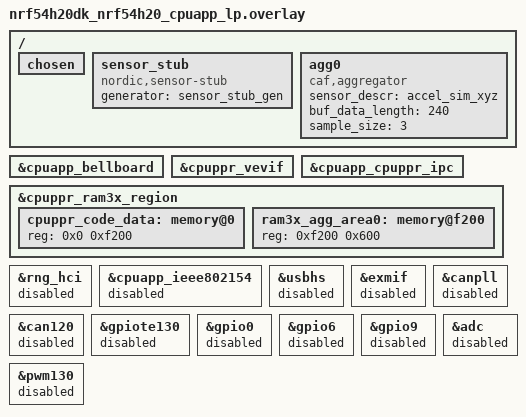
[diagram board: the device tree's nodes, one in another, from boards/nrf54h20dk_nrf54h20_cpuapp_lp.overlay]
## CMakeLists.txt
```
#
# Copyright (c) 2022 Nordic Semiconductor
#
# SPDX-License-Identifier: LicenseRef-Nordic-5-Clause
#
cmake_minimum_required(VERSION 3.20.0)

find_package(Zephyr REQUIRED HINTS $ENV{ZEPHYR_BASE})
project("Sensor manager sample")

target_sources(app PRIVATE src/main.c)

# Add include directory for board specific CAF def files
zephyr_include_directories(
  configuration/
  configuration/${NORMALIZED_BOARD_TARGET}
)

add_subdirectory(src/modules)
```

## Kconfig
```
#
# Copyright (c) 2022 Nordic Semiconductor ASA
#
# SPDX-License-Identifier: LicenseRef-Nordic-5-Clause
#

menu "Sensor manager sample"
rsource "src/modules/Kconfig"
endmenu

menu "Zephyr Kernel"
source "Kconfig.zephyr"
endmenu
```

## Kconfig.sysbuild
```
#
# Copyright (c) 2024 Nordic Semiconductor ASA
#
# SPDX-License-Identifier: LicenseRef-Nordic-5-Clause
#

config INCLUDE_REMOTE_IMAGE
	bool "Include CAF Sensor Manager remote image"
	default y

config REMOTE_BOARD
	string
	default "nrf5340dk/nrf5340/cpunet" if BOARD_NRF5340DK_NRF5340_CPUAPP
	default "nrf5340dk/nrf5340/cpunet" if BOARD_NRF5340DK_NRF5340_CPUAPP_NS
	default "nrf54h20dk/nrf54h20/cpuppr" if BOARD_NRF54H20DK_NRF54H20_CPUAPP

source "share/sysbuild/Kconfig"
```

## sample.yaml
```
sample:
  description: Sample showing CAF sensor manager usage
  name: CAF sensor manager sample

tests:
  sample.caf_sensor_manager.correctness_test:
    sysbuild: true
    build_only: false
    harness: console
    platform_allow:
      - nrf52840dk/nrf52840
      - nrf5340dk/nrf5340/cpuapp
      - qemu_cortex_m3
    integration_platforms:
      - nrf52840dk/nrf52840
      - nrf5340dk/nrf5340/cpuapp
      - qemu_cortex_m3
    harness_config:
      type: multi_line
      ordered: true
      regex:
        - "main: Event manager initialized"
        - "main state:READY"
        - "Send sensor buffer desc address:"
        - "sensor_data_aggregator_release_buffer_event"
    tags:
      - sysbuild
      - ci_samples_caf_sensor_manager
  sample.caf_sensor_manager.nrf52840dk.power_consumption_test:
    sysbuild: true
    build_only: true
    platform_allow: nrf52840dk/nrf52840
    integration_platforms:
      - nrf52840dk/nrf52840
    extra_args:
      - CONFIG_SERIAL=n
      - CONFIG_CONSOLE=n
      - CONFIG_UART_CONSOLE=n
      - CONFIG_LOG=n
    tags:
      - sysbuild
      - ci_samples_caf_sensor_manager
  sample.caf_sensor_manager.multi_core.power_consumption_test:
    sysbuild: true
    build_only: true
    platform_allow: nrf5340dk/nrf5340/cpuapp
    integration_platforms:
      - nrf5340dk/nrf5340/cpuapp
    extra_args:
      - CONFIG_SERIAL=n
      - CONFIG_CONSOLE=n
      - CONFIG_UART_CONSOLE=n
      - CONFIG_LOG=n
      - remote_CONFIG_SERIAL=n
      - remote_CONFIG_CONSOLE=n
      - remote_CONFIG_UART_CONSOLE=n
      - remote_CONFIG_LOG=n
    tags:
      - sysbuild
      - ci_samples_caf_sensor_manager
  sample.caf_sensor_manager.nrf5340dk_singlecore.power_consumption_test:
    sysbuild: true
    build_only: true
    platform_allow: nrf5340dk/nrf5340/cpuapp
    integration_platforms:
      - nrf5340dk/nrf5340/cpuapp
    extra_args:
      - FILE_SUFFIX=singlecore
      - CONFIG_CONSOLE=n
      - CONFIG_UART_CONSOLE=n
      - CONFIG_LOG=n
    tags:
      - sysbuild
      - ci_samples_caf_sensor_manager
  sample.caf_sensor_manager.nrf5340dk_singlecore.correctness_test:
    sysbuild: true
    build_only: false
    platform_allow: nrf5340dk/nrf5340/cpuapp
    integration_platforms:
      - nrf5340dk/nrf5340/cpuapp
    extra_args: FILE_SUFFIX=singlecore
    harness: console
    harness_config:
      type: multi_line
      ordered: true
      regex:
        - "main: Event manager initialized"
        - "main state:READY"
        - "Send sensor buffer desc address:"
        - "sensor_data_aggregator_release_buffer_event"
    tags:
      - sysbuild
      - ci_samples_caf_sensor_manager
  sample.caf_sensor_manager.nrf54h20.multicore:
    build_only: true
    sysbuild: true
    platform_allow:
      - nrf54h20dk/nrf54h20/cpuapp
    integration_platforms:
      - nrf54h20dk/nrf54h20/cpuapp
    extra_args: caf_sensor_manager_SNIPPET=nordic-ppr
    tags:

      - sysbuild
      - ci_samples_caf_sensor_manager
  sample.caf_sensor_manager.nrf54h20.singlecore:
    build_only: true
    sysbuild: true
    platform_allow:
      - nrf54h20dk/nrf54h20/cpuapp
    integration_platforms:
      - nrf54h20dk/nrf54h20/cpuapp
    extra_args: FILE_SUFFIX=singlecore
    tags:
      - sysbuild
      - ci_samples_caf_sensor_manager
  sample.caf_sensor_manager.nrf54h20.multicore.power_consumption_test:
    build_only: true
    sysbuild: true
    platform_allow:
      - nrf54h20dk/nrf54h20/cpuapp
    integration_platforms:
      - nrf54h20dk/nrf54h20/cpuapp
    extra_args:
      - caf_sensor_manager_SNIPPET=nordic-ppr
      - SB_CONFIG_NETCORE_EMPTY=y
      - CONFIG_PM=y
    tags:
      - sysbuild
      - ci_samples_caf_sensor_manager
  sample.caf_sensor_manager.nrf54h20.singlecore.power_consumption_test:
    build_only: true
    sysbuild: true
    platform_allow:
      - nrf54h20dk/nrf54h20/cpuapp
    integration_platforms:
      - nrf54h20dk/nrf54h20/cpuapp
    extra_args:
      - FILE_SUFFIX=singlecore
      - SB_CONFIG_NETCORE_EMPTY=y
      - CONFIG_PM=y
    tags:
      - sysbuild
      - ci_samples_caf_sensor_manager
```

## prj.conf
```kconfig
#
# Copyright (c) 2022 Nordic Semiconductor ASA
#
# SPDX-License-Identifier: LicenseRef-Nordic-5-Clause
#
################################################################################
# Application configuration

CONFIG_APP_WORKLOAD_SIM=y

CONFIG_CAF=y

CONFIG_CAF_INIT_LOG_SENSOR_EVENTS=n

CONFIG_CAF_SENSOR_DATA_AGGREGATOR_EVENTS=y

CONFIG_APP_EVENT_MANAGER=y
CONFIG_REBOOT=y
CONFIG_HEAP_MEM_POOL_SIZE=4096

################################################################################
# Debug configuration

CONFIG_ASSERT=y
CONFIG_RESET_ON_FATAL_ERROR=n

# Disable GPIO
CONFIG_GPIO=n

CONFIG_LOG=y
CONFIG_LOG_MODE_DEFERRED=y
```

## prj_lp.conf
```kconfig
#
# Copyright (c) 2025 Nordic Semiconductor ASA
#
# SPDX-License-Identifier: LicenseRef-Nordic-5-Clause
#
################################################################################
# Application configuration

CONFIG_APP_WORKLOAD_SIM=y

CONFIG_CAF=y

CONFIG_CAF_INIT_LOG_SENSOR_EVENTS=n

CONFIG_CAF_SENSOR_DATA_AGGREGATOR_EVENTS=y

CONFIG_APP_EVENT_MANAGER=y
CONFIG_REBOOT=y
CONFIG_HEAP_MEM_POOL_SIZE=4096

################################################################################
# Debug configuration

CONFIG_ASSERT=y
CONFIG_RESET_ON_FATAL_ERROR=n

# Disable GPIO
CONFIG_GPIO=n

CONFIG_LOG=y
CONFIG_LOG_MODE_DEFERRED=y

CONFIG_PM=y
CONFIG_PM_S2RAM=y
CONFIG_PM_S2RAM_CUSTOM_MARKING=y
```

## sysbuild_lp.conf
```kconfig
#
# Copyright (c) 2025 Nordic Semiconductor ASA
#
# SPDX-License-Identifier: LicenseRef-Nordic-5-Clause
#
################################################################################

SB_CONFIG_NETCORE_EMPTY=y
```

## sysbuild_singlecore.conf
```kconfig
#
# Copyright (c) 2024 Nordic Semiconductor ASA
#
# SPDX-License-Identifier: LicenseRef-Nordic-5-Clause
#
################################################################################

SB_CONFIG_INCLUDE_REMOTE_IMAGE=n
```

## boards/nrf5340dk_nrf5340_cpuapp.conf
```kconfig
#
# Copyright (c) 2022 Nordic Semiconductor ASA
#
# SPDX-License-Identifier: LicenseRef-Nordic-5-Clause
#
################################################################################

CONFIG_EVENT_MANAGER_PROXY=y
CONFIG_IPC_SERVICE=y
CONFIG_MBOX=y

CONFIG_OPENAMP=y
CONFIG_OPENAMP_SLAVE=n

CONFIG_CAF_SENSOR_DATA_AGGREGATOR_EVENTS=y

CONFIG_SOC_NRF53_CPUNET_ENABLE=y
```

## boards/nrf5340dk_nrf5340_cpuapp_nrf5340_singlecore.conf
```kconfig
#
# Copyright (c) 2022 Nordic Semiconductor ASA
#
# SPDX-License-Identifier: LicenseRef-Nordic-5-Clause
#
################################################################################

CONFIG_APP_INCLUDE_REMOTE_IMAGE=n
CONFIG_APP_REMOTE_BOARD=""

CONFIG_EVENT_MANAGER_PROXY=n
CONFIG_IPC_SERVICE=n
CONFIG_MBOX=n
CONFIG_NRF53_SYNC_RTC=n
CONFIG_OPENAMP=n

CONFIG_CAF_SENSOR_MANAGER=y

CONFIG_SENSOR=y
CONFIG_SENSOR_SIM=y
```

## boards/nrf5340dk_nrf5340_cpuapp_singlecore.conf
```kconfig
#
# Copyright (c) 2022 Nordic Semiconductor ASA
#
# SPDX-License-Identifier: LicenseRef-Nordic-5-Clause
#
################################################################################

CONFIG_EVENT_MANAGER_PROXY=n
CONFIG_IPC_SERVICE=n
CONFIG_MBOX=n
CONFIG_NRF53_SYNC_RTC=n
CONFIG_OPENAMP=n

CONFIG_CAF_SENSOR_MANAGER=y
CONFIG_CAF_SENSOR_MANAGER_THREAD_STACK_SIZE=512
CONFIG_CAF_SENSOR_DATA_AGGREGATOR=y

CONFIG_SENSOR=y
CONFIG_SENSOR_STUB=y
```

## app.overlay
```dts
/*
 * Copyright (c) 2022 Nordic Semiconductor ASA
 *
 * SPDX-License-Identifier: LicenseRef-Nordic-5-Clause
 */

/ {
	agg0: agg0 {
		compatible = "caf,aggregator";
		sensor_descr = "accel_sim_xyz";
		buf_data_length = <240>;
		sample_size = <3>;
		status = "okay";
	};
};
```

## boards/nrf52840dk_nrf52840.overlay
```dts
/*
 * Copyright (c) 2022 Nordic Semiconductor ASA
 *
 * SPDX-License-Identifier: LicenseRef-Nordic-5-Clause
 */

/ {
	sensor_stub: sensor_stub {
		compatible = "nordic,sensor-stub";
		generator = "sensor_stub_gen";
		status = "okay";
	};

	agg0: agg0 {
		compatible = "caf,aggregator";
		sensor_descr = "accel_sim_xyz";
		buf_data_length = <240>;
		sample_size = <3>;
		status = "okay";
	};
};
```

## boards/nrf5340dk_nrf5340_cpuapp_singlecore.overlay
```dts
/*
 * Copyright (c) 2022 Nordic Semiconductor ASA
 *
 * SPDX-License-Identifier: LicenseRef-Nordic-5-Clause
 */

/ {
	agg0: agg0 {
		compatible = "caf,aggregator";
		sensor_descr = "accel_sim_xyz";
		buf_data_length = <240>;
		sample_size = <3>;
		status = "okay";
	};

	sensor_stub: sensor_stub {
		compatible = "nordic,sensor-stub";
		generator = "sensor_stub_gen";
		status = "okay";
	};
};
```

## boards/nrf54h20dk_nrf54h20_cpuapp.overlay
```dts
/*
 * Copyright (c) 2024 Nordic Semiconductor ASA
 *
 * SPDX-License-Identifier: LicenseRef-Nordic-5-Clause
 */

/* Replace default ipc0 instance */
/delete-node/ &ipc0;

/ {
	chosen {
		/delete-property/ zephyr,bt-hci;
	};

	sensor_stub: sensor_stub {
		compatible = "nordic,sensor-stub";
		generator = "sensor_stub_gen";
		status = "okay";
	};

	agg0: agg0 {
		compatible = "caf,aggregator";
		sensor_descr = "accel_sim_xyz";
		buf_data_length = <240>;
		sample_size = <3>;
	};

	reserved-memory {
		cpuppr_code_data: memory@2fc00000 {
			reg = <0x2fc00000 0xf200>;
		};

		ram3x_agg_area0: memory@2fc0f200 {
			reg = <0x2fc0f200 0x600>;
		};
	};
};

/* Enabled nodes required by IPC
 * Two mboxes, one for each sides and one ipc instance
 */

&cpuapp_bellboard {
	status = "okay";
};

&cpuppr_vevif {
	status = "okay";
};

ipc0: &cpuapp_cpuppr_ipc {
	status = "okay";
};

/* UART and RAM3 instance used by PPR should be enabled at build time
 * using nordic-ppr snippet.
 */
```

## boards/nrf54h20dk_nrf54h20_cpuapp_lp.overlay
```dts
/*
 * Copyright (c) 2025 Nordic Semiconductor ASA
 *
 * SPDX-License-Identifier: LicenseRef-Nordic-5-Clause
 */

 /* Replace default ipc0 instance */
/delete-node/ &ipc0;

/ {
	chosen {
		/delete-property/ zephyr,bt-hci;
		/delete-property/ zephyr,ieee802154;
	};

	sensor_stub: sensor_stub {
		compatible = "nordic,sensor-stub";
		generator = "sensor_stub_gen";
		status = "okay";
	};

	agg0: agg0 {
		compatible = "caf,aggregator";
		sensor_descr = "accel_sim_xyz";
		buf_data_length = <240>;
		sample_size = <3>;
	};
};

/* Enabled nodes required by IPC
 * Two mboxes, one for each sides and one ipc instance
 */

&cpuapp_bellboard {
	status = "okay";
};

&cpuppr_vevif {
	status = "okay";
};

ipc0: &cpuapp_cpuppr_ipc {
	status = "okay";
};

&cpuppr_ram3x_region {
	cpuppr_code_data: memory@0 {
		reg = <0x0 0xf200>;
	};

	ram3x_agg_area0: memory@f200 {
		reg = <0xf200 0x600>;
	};
};

/* UART and RAM3 instance used by PPR should be enabled at build time
 * using nordic-ppr snippet.
 */

/* Disable unused devices */

&rng_hci {
	status = "disabled";
};

&cpuapp_ieee802154 {
	status = "disabled";
};

&usbhs {
	status = "disabled";
};

&exmif {
	status = "disabled";
};

&canpll {
	status = "disabled";
};

&can120 {
	status = "disabled";
};

&gpiote130 {
	status = "disabled";
};

&gpio0 {
	status = "disabled";
};

&gpio6 {
	status = "disabled";
};

&gpio9 {
	status = "disabled";
};

&adc {
	status = "disabled";
};

&pwm130 {
	status = "disabled";
};
```

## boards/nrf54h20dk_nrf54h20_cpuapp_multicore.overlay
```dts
/*
 * Copyright (c) 2024 Nordic Semiconductor ASA
 *
 * SPDX-License-Identifier: LicenseRef-Nordic-5-Clause
 */

 /* Replace default ipc0 instance */
/delete-node/ &ipc0;

/ {
	sensor_stub: sensor_stub {
		compatible = "nordic,sensor-stub";
		generator = "sensor_stub_gen";
		status = "okay";
	};

	agg0: agg0 {
		compatible = "caf,aggregator";
		sensor_descr = "accel_sim_xyz";
		buf_data_length = <240>;
		sample_size = <3>;
	};
};

/* Enabled nodes required by IPC
 * Two mboxes, one for each sides and one ipc instance
 */

&cpuapp_bellboard {
	status = "okay";
};

&cpuppr_vevif {
       status = "okay";
};

ipc0: &cpuapp_cpuppr_ipc {
	status = "okay";
};

/* UART and RAM3 instance used by PPR should be enabled at build time
 * using nordic-ppr snippet.
 */
```

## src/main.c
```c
/*
 * Copyright (c) 2022 Nordic Semiconductor ASA
 *
 * SPDX-License-Identifier: LicenseRef-Nordic-5-Clause
 */

#include <zephyr/kernel.h>
#include <app_event_manager.h>

#define MODULE main

#include <caf/events/module_state_event.h>
#include <zephyr/logging/log.h>

LOG_MODULE_REGISTER(MODULE);

#include "event_proxy_init.h"

int main(void)
{
	int ret;

	ret = app_event_manager_init();
	if (ret) {
		LOG_ERR("Event Manager not initialized, err: %d", ret);
		__ASSERT_NO_MSG(false);
		return 0;
	}
	LOG_INF("Event manager initialized");

	ret = init_event_proxy("sensor_data_aggregator_event");
	if (ret) {
		LOG_ERR("Event Manager Proxy not initialized, err: %d", ret);
		__ASSERT_NO_MSG(false);
		return 0;
	}

	module_set_state(MODULE_STATE_READY);

	return 0;
}
```
